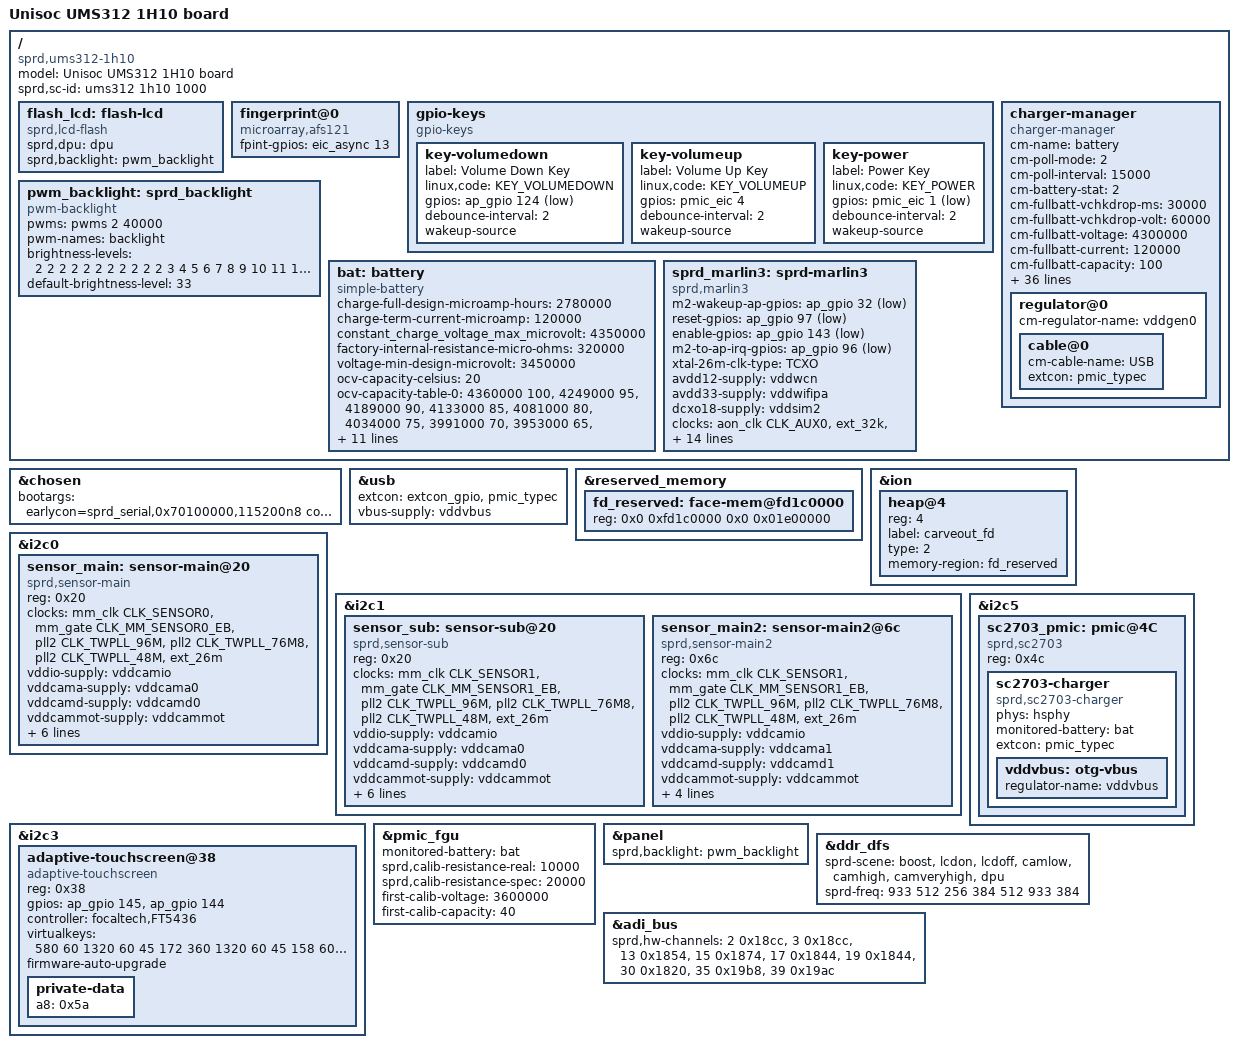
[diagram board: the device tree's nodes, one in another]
/dts-v1/;
/plugin/;

#include <dt-bindings/input/input.h>
#include <dt-bindings/gpio/gpio.h>
#include <dt-bindings/clock/sprd,sharkl5-clk.h>
#include <dt-bindings/mfd/sprd,sc2730-regs.h>
#include <dt-bindings/mfd/sprd,sc2730-mask.h>

/ {
	model = "Unisoc UMS312 1H10 board";

	compatible = "sprd,ums312-1h10";

	sprd,sc-id = "ums312 1h10 1000";

	fragment {
		target-path = "/";
		__overlay__ {
			flash_lcd: flash-lcd {
				compatible = "sprd,lcd-flash";
				sprd,dpu = <&dpu>;
				sprd,backlight = <&pwm_backlight>;
				status = "okay";
			};

			fingerprint@0 {
				compatible = "microarray,afs121";
				fpint-gpios = <&eic_async 13 0>;
			};

			gpio-keys {
				compatible = "gpio-keys";

				key-volumedown {
					label = "Volume Down Key";
					linux,code = <KEY_VOLUMEDOWN>;
					gpios = <&ap_gpio 124 GPIO_ACTIVE_LOW>;
					debounce-interval = <2>;
					wakeup-source;
				};

				key-volumeup {
					label = "Volume Up Key";
					linux,code = <KEY_VOLUMEUP>;
					gpios = <&pmic_eic 4 GPIO_ACTIVE_HIGH>;
					debounce-interval = <2>;
					wakeup-source;
				};

				key-power {
					label = "Power Key";
					linux,code = <KEY_POWER>;
					gpios = <&pmic_eic 1 GPIO_ACTIVE_LOW>;
					debounce-interval = <2>;
					wakeup-source;
				};
			};

			pwm_backlight: sprd_backlight {
				compatible = "pwm-backlight";
				pwms = <&pwms 2 40000>;
				pwm-names = "backlight";
				brightness-levels = <
						  2   2   2   2   2   2   2   2
					  2   2   2   3   4   5   6   7   8   9
					 10  11  12  13  14  15  16  17  18  19
					 20  21  22  23  24  25  26  27  28  29
					 30  31  32  33  34  35  36  37  38  39
					 40  41  42  43  44  45  46  47  48  49
					 50  51  52  53  54  55  56  57  58  59
					 60  61  62  63  64  65  66  67  68  69
					 70  71  72  73  74  75  76  77  78  79
					 80  81  82  83  84  85  86  87  88  89
					 90  91  92  93  94  95  96  97  98  99
					100 101 102 103 104 105 106 107 108 109
					110 111 112 113 114 115 116 117 118 119
					120 121 122 123 124 125 126 127 128 129
					130 131 132 133 134 135 136 137 138 139
					140 141 142 143 144 145 146 147 148 149
					150 151 152 153 154 155 156 157 158 159
					160 161 162 163 164 165 166 167 168 169
					170 171 172 173 174 175 176 177 178 179
					180 181 182 183 184 185 186 187 188 189
					190 191 192 193 194 195 196 197 198 199
					200 201 202 203 204 205 206 207 208 209
					210 211 212 213 214 215 216 217 218 219
					220 221 222 223 224 225 226 227 228 229
					230 231 232 233 234 235 236 237 238 239
					240 241 242 243 244 245 246 247
					>;
				default-brightness-level = <33>;
			};

			bat: battery {
				compatible = "simple-battery";
				charge-full-design-microamp-hours = <2780000>;
				charge-term-current-microamp = <120000>;
				constant_charge_voltage_max_microvolt = <4350000>;
				factory-internal-resistance-micro-ohms = <320000>;
				voltage-min-design-microvolt = <3450000>;
				ocv-capacity-celsius = <20>;
				ocv-capacity-table-0 = <4360000 100>, <4249000 95>, <4189000 90>,
							<4133000 85>, <4081000 80>, <4034000 75>,
							<3991000 70>, <3953000 65>, <3910000 60>,
							<3866000 55>, <3836000 50>, <3813000 45>,
							<3795000 40>, <3782000 35>, <3774000 30>,
							<3765000 25>, <3750000 20>, <3726000 15>,
							<3687000 10>, <3658000 5>, <3400000 0>;
				capacity-temp-table = <25 100>, <10 97>, <(-10) 60>;
				resistance-temp-table = <20 100>, <10 243>, <(-10) 468>;
				charge-sdp-current-microamp = <500000 500000>;
				charge-dcp-current-microamp = <2000000 3000000>;
				charge-cdp-current-microamp = <1150000 1150000>;
				charge-unknown-current-microamp = <500000 500000>;
			};

			charger-manager {
				compatible = "charger-manager";
				cm-name = "battery";
				cm-poll-mode = <2>;
				cm-poll-interval = <15000>;
				cm-battery-stat = <2>;

				cm-fullbatt-vchkdrop-ms = <30000>;
				cm-fullbatt-vchkdrop-volt = <60000>;
				cm-fullbatt-voltage = <4300000>;
				cm-fullbatt-current = <120000>;
				cm-fullbatt-capacity = <100>;

				cm-num-chargers = <1>;
				cm-chargers = "sc2703_charger";
				cm-fuel-gauge = "sc27xx-fgu";

				/* in deci centigrade */
				cm-battery-cold = <200>;
				cm-battery-cold-in-minus;
				cm-battery-hot = <800>;
				cm-battery-temp-diff = <100>;

				/* Allow charging for 6hr */
				cm-charging-max = <18000000>;

				/* the interval to feed charger watchdog */
				cm-wdt-interval = <60>;

				/* drop voltage in microVolts to allow shutdown */
				cm-shutdown-voltage = <3100000>;

				/* when 99% of the time is exceeded, it will be forced to 100% */
				cm-tickle-time-out = <1500>;

				/* how much time to allow capacity change */
				cm-one-cap-time = <30>;

				/* when the safe charging voltage is exceeded, stop charging */
				cm-charge-voltage-max = <6500000>;
				/* drop voltage in microVolts to restart charging */
				cm-charge-voltage-drop = <700000>;
				cm-thermal-zone = "board-thmzone";
				cm-dcp-jeita-temp-table = <1000 1030 0 4350000>, <1150 1180 700000 4350000>,
					<1450 1420 2000000 4350000>, <1600 1570 700000 4100000>;
				cm-sdp-jeita-temp-table = <1000 1030 0 4350000>, <1150 1180 500000 4350000>,
					<1450 1420 500000 4350000>, <1600 1570 500000 4100000>;
				cm-cdp-jeita-temp-table = <1000 1030 0 4350000>, <1150 1180 700000 4350000>,
					<1450 1420 1150000 4350000>, <1600 1570 700000 4100000>;
				cm-unknown-jeita-temp-table = <1000 1030 0 4350000>, <1150 1180 500000 4350000>,
					<1450 1420 500000 4350000>, <1600 1570 500000 4100000>;

				monitored-battery = <&bat>;
				cm-capacity-track;

				cm-cap-remap-table = <1 2 3>, <2 3 2>, <98 99 2>, <99 100 3>;

				regulator@0 {
					cm-regulator-name = "vddgen0";
					cable@0 {
						cm-cable-name = "USB";
						extcon = <&pmic_typec>;
					};
				};
			};

			sprd_marlin3: sprd-marlin3 {
				compatible = "sprd,marlin3";
				m2-wakeup-ap-gpios = <&ap_gpio 32 GPIO_ACTIVE_LOW>;
				reset-gpios = <&ap_gpio 97 GPIO_ACTIVE_LOW>;
				enable-gpios = <&ap_gpio 143 GPIO_ACTIVE_LOW>;
				m2-to-ap-irq-gpios = <&ap_gpio 96 GPIO_ACTIVE_LOW>;
				xtal-26m-clk-type = "TCXO";
				avdd12-supply = <&vddwcn>;
				avdd33-supply = <&vddwifipa>;
				dcxo18-supply = <&vddsim2>;

				clock-names = "clk_32k","source","enable";
				clocks = <&aon_clk CLK_AUX0>,
					 <&ext_32k>,
					 <&aonapb_gate CLK_AUX0_EB>;

				sdhci-name = <&sdio1>;
				sprd,btwf-file-name = "/dev/block/platform/soc/soc:ap-apb/71400000.sdio/by-name/wcnmodem";
				sprd,gnss-file-name = "/dev/block/platform/soc/soc:ap-apb/71400000.sdio/by-name/gnssmodem";
				adma-tx;
				adma-rx;
				/*
				 * bound parameter:
				 * [0]:addr offset, [1]:mask, [2]:unboundval, [3]:boundval
				 */
				avdd12-parent-bound-chip = <REG_ANA_SLP_DCDC_PD_CTRL MASK_ANA_SLP_DCDCGEN1_PD_EN 0x0 MASK_ANA_SLP_DCDCGEN1_PD_EN>;
				avdd12-bound-wbreq = <REG_ANA_LDO_XTL_EN10 MASK_ANA_LDO_VDDWCN_EXT_XTL3_EN 0x0 MASK_ANA_LDO_VDDWCN_EXT_XTL3_EN>;
				avdd33-bound-wbreq = <REG_ANA_LDO_XTL_EN11 MASK_ANA_LDO_VDDWIFIPA_EXT_XTL3_EN 0x0 MASK_ANA_LDO_VDDWIFIPA_EXT_XTL3_EN>;
			};
		};
	};
};

&chosen {
	bootargs = "earlycon=sprd_serial,0x70100000,115200n8 console=ttyS1,115200n8 loglevel=1 init=/init root=/dev/ram0 ro rootwait androidboot.hardware=ums312_1h10 androidboot.dtbo_idx=0 swiotlb=1 printk.devkmsg=on androidboot.boot_devices=soc/soc:ap-apb/71400000.sdio";
};

&usb {
	extcon = <&extcon_gpio>, <&pmic_typec>;
	vbus-supply = <&vddvbus>;
};

&reserved_memory {

	fd_reserved: face-mem@fd1c0000{
		reg = <0x0 0xfd1c0000 0x0 0x01e00000>;
	};
};

&ion {
	heap@4 {
		reg = <4>;
		label = "carveout_fd";
		type = <2>;
		memory-region = <&fd_reserved>;
	};
};

&i2c0 {
	status = "okay";

	sensor_main: sensor-main@20 {
		compatible = "sprd,sensor-main";
		reg = <0x20>;

		clock-names = "clk_src","sensor_eb",
			"clk_96m","clk_76m8",
			"clk_48m","clk_26m";
		clocks = <&mm_clk CLK_SENSOR0>,<&mm_gate CLK_MM_SENSOR0_EB>,
			<&pll2 CLK_TWPLL_96M>,<&pll2 CLK_TWPLL_76M8>,
			<&pll2 CLK_TWPLL_48M>,<&ext_26m>;
		vddio-supply = <&vddcamio>;
		vddcama-supply = <&vddcama0>;
		vddcamd-supply = <&vddcamd0>;
		vddcammot-supply = <&vddcammot>;
		sprd,phyid = <0>;
		csi = <&csi0>;
		reset-gpios = <&ap_gpio 44 0>;
		power-down-gpios = <&ap_gpio 46 0>;
		mipi-switch-en-gpios = <&ap_gpio 55 0>;
		/* 0:front, 1:main sensor */
		mipi-switch-mode-gpios = <&ap_gpio 156 0>;

		status = "okay";
	};
};

&i2c1 {
	status = "okay";

	sensor_sub: sensor-sub@20 {
		compatible = "sprd,sensor-sub";
		reg = <0x20>;

		clock-names = "clk_src","sensor_eb",
			"clk_96m","clk_76m8",
			"clk_48m","clk_26m";
		clocks = <&mm_clk CLK_SENSOR1>,<&mm_gate CLK_MM_SENSOR1_EB>,
			<&pll2 CLK_TWPLL_96M>,<&pll2 CLK_TWPLL_76M8>,
			<&pll2 CLK_TWPLL_48M>,<&ext_26m>;
		vddio-supply = <&vddcamio>;
		vddcama-supply = <&vddcama0>;
		vddcamd-supply = <&vddcamd0>;
		vddcammot-supply = <&vddcammot>;
		sprd,phyid = <0>;
		csi = <&csi0>;
		reset-gpios = <&ap_gpio 41 0>;
		power-down-gpios = <&ap_gpio 40 0>;
		mipi-switch-en-gpios = <&ap_gpio 55 0>;
		/* 0:front, 1:main sensor */
		mipi-switch-mode-gpios = <&ap_gpio 156 0>;

		status = "okay";
	};

	sensor_main2: sensor-main2@6c {
		compatible = "sprd,sensor-main2";
		reg = <0x6c>;

		clock-names = "clk_src","sensor_eb",
			"clk_96m","clk_76m8",
			"clk_48m","clk_26m";
		clocks = <&mm_clk CLK_SENSOR1>,<&mm_gate CLK_MM_SENSOR1_EB>,
			<&pll2 CLK_TWPLL_96M>,<&pll2 CLK_TWPLL_76M8>,
			<&pll2 CLK_TWPLL_48M>,<&ext_26m>;
		vddio-supply = <&vddcamio>;
		vddcama-supply = <&vddcama1>;
		vddcamd-supply = <&vddcamd1>;
		vddcammot-supply = <&vddcammot>;
		sprd,phyid = <3>;
		csi = <&csi1>;
		reset-gpios = <&ap_gpio 45 0>;
		power-down-gpios = <&ap_gpio 47 0>;

		status = "okay";
	};
};

&i2c3 {
	status = "okay";

	adaptive-touchscreen@38 {
		compatible = "adaptive-touchscreen";
		reg = <0x38>;
		gpios = <&ap_gpio 145 GPIO_ACTIVE_HIGH
			&ap_gpio 144 GPIO_ACTIVE_HIGH>;
		controller = "focaltech,FT5436";
		virtualkeys = <580 60 1320 60 45
				172 360 1320 60 45
				158 600 1320 60 45>;
		firmware-auto-upgrade;
		private-data {
			a8 = /bits/ 8 <0x5a>;
		};
	};
};

&i2c5 {
	status = "okay";

	sc2703_pmic: pmic@4C {
		compatible = "sprd,sc2703";
		reg = <0x4c>;
		sc2703-charger {
			compatible = "sprd,sc2703-charger";
			phys = <&hsphy>;
			monitored-battery = <&bat>;
			extcon = <&pmic_typec>;
			vddvbus:otg-vbus {
				regulator-name = "vddvbus";
			};
		};
	};
};

&pmic_fgu {
	monitored-battery = <&bat>;
	sprd,calib-resistance-real = <10000>;
	sprd,calib-resistance-spec = <20000>;
	first-calib-voltage = <3600000>;
	first-calib-capacity = <40>;
};

&panel {
	sprd,backlight = <&pwm_backlight>;
};

&ddr_dfs {
	sprd-scene = "boost", "lcdon", "lcdoff", "camlow",
		"camhigh", "camveryhigh", "dpu";
	sprd-freq = <933 512 256 384 512 933 384>;
};

&adi_bus {
	sprd,hw-channels = <2 0x18cc>, <3 0x18cc>, <13 0x1854>, <15 0x1874>,
			   <17 0x1844>, <19 0x1844>, <30 0x1820>, <35 0x19b8>,
			   <39 0x19ac>;
};
